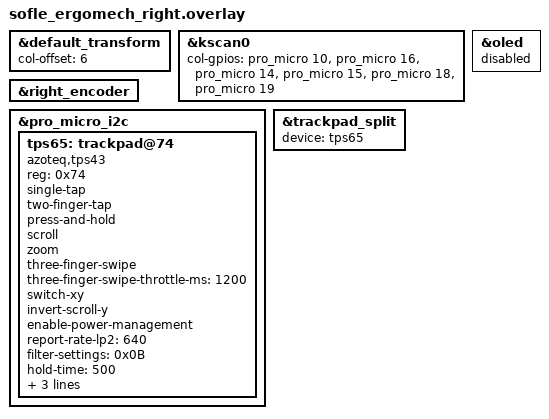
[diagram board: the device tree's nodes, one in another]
/*
 * Copyright (c) 2020 Ryan Cross
 *
 * SPDX-License-Identifier: MIT
 */

#include "sofle_ergomech.dtsi"

&default_transform {
    col-offset = <6>;
};

&kscan0 {
    col-gpios
        = <&pro_micro 10 GPIO_ACTIVE_HIGH>
        , <&pro_micro 16 GPIO_ACTIVE_HIGH>
        , <&pro_micro 14 GPIO_ACTIVE_HIGH>
        , <&pro_micro 15 GPIO_ACTIVE_HIGH>
        , <&pro_micro 18 GPIO_ACTIVE_HIGH>
        , <&pro_micro 19 GPIO_ACTIVE_HIGH>
        ;
};

&right_encoder {
    status = "okay";
};

// The trackpad replaces the OLED display on the right side, so the I2C bus is
// used by the trackpad instead of the SSD1306 display.
&oled {
    status = "disabled";
};

&pro_micro_i2c {
    status = "okay";

    tps65: trackpad@74 {
        compatible = "azoteq,tps43";
        reg = <0x74>;
        status = "okay";

        // Gestures
        single-tap;
        two-finger-tap;
        press-and-hold;
        scroll;
        zoom;
        three-finger-swipe;
        three-finger-swipe-throttle-ms = <1200>;
        switch-xy;
        invert-scroll-y;

        // Power management
        enable-power-management;
        // idle-sleep; // maximal power savings, but the trackpad takes ~300ms to
        //             // respond when the keyboard is idle. Not recommended.
        report-rate-lp2 = <640>; // 640ms report rate in LP2 state means 55uA draw
                                  // rather than default 160ms 174uA draw

        // Tuning
        filter-settings = <0x0B>;
        hold-time = <500>;
        scroll-angle = <30>; // The default angle (~47 deg) is too big
        sensitivity = <100>;
        scroll-sensitivity = <100>;
    };
};

&trackpad_split {
    device = <&tps65>;
};
